VERSION "1.0"

NS_ :

BS_:

BU_: ECU

SGTYPE_ TempType : 16@1+ (0.1,-40) [-40|200] "degC" 0 ;
SGTYPE_ PressureType : 16@1+ (0.01,0) [0|655.35] "kPa" 0 ;

SGTYPE_VAL_ TempType 0 "Cold" 1 "Normal" 2 "Hot" ;

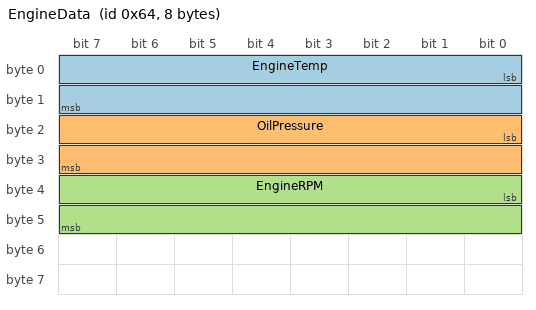
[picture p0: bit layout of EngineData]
BO_ 100 EngineData: 8 ECU
 SG_ EngineTemp : 0|16@1+ (0.1,-40) [-40|200] "degC" Vector__XXX
 SG_ OilPressure : 16|16@1+ (0.01,0) [0|655.35] "kPa" Vector__XXX
 SG_ EngineRPM : 32|16@1+ (1,0) [0|8000] "rpm" Vector__XXX

SIG_TYPE_REF_ 100 EngineTemp : TempType ;
SIG_TYPE_REF_ 100 OilPressure : PressureType ;
